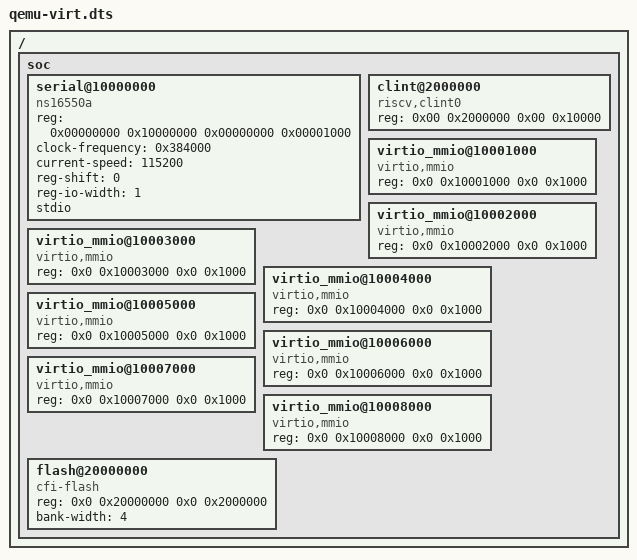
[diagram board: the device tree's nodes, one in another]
/dts-v1/;

/ {
	soc {
		#address-cells = <2>;
		#size-cells = <2>;

		serial@10000000 {
			compatible = "ns16550a";
			reg = <0x00000000 0x10000000 0x00000000 0x00001000>;
			clock-frequency = <0x384000>;
			current-speed = <115200>;
			reg-shift = <0>;
			reg-io-width = <1>;
			stdio;
 		};

		clint@2000000 {
			reg = <0x00 0x2000000 0x00 0x10000>;
			compatible = "riscv,clint0";
		};

		virtio_mmio@10001000 { compatible = "virtio,mmio"; reg = <0x0 0x10001000 0x0 0x1000>; };
		virtio_mmio@10002000 { compatible = "virtio,mmio"; reg = <0x0 0x10002000 0x0 0x1000>; };
		virtio_mmio@10003000 { compatible = "virtio,mmio"; reg = <0x0 0x10003000 0x0 0x1000>; };
		virtio_mmio@10004000 { compatible = "virtio,mmio"; reg = <0x0 0x10004000 0x0 0x1000>; };
		virtio_mmio@10005000 { compatible = "virtio,mmio"; reg = <0x0 0x10005000 0x0 0x1000>; };
		virtio_mmio@10006000 { compatible = "virtio,mmio"; reg = <0x0 0x10006000 0x0 0x1000>; };
		virtio_mmio@10007000 { compatible = "virtio,mmio"; reg = <0x0 0x10007000 0x0 0x1000>; };
		virtio_mmio@10008000 { compatible = "virtio,mmio"; reg = <0x0 0x10008000 0x0 0x1000>; };

		flash@20000000 {
			compatible = "cfi-flash";
			reg = <0x0 0x20000000 0x0 0x2000000>;
			bank-width = <4>;
		};
	};
};
